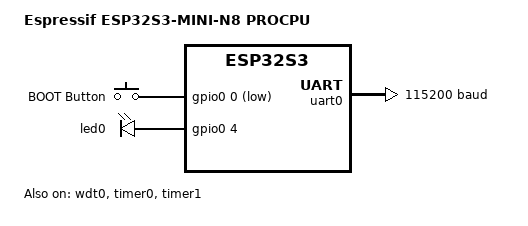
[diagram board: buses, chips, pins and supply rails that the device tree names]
/*
* Copyright (c) 2022-2025 ELIUS FAUSTINE
*
* SPDX-License-Identifier: Apache-2.0
*/
/dts-v1/;

#include <espressif/esp32s3/esp32s3_mini_n8.dtsi>
#include <zephyr/dt-bindings/input/input-event-codes.h>
#include <zephyr/dt-bindings/input/esp32-touch-sensor-input.h>
#include <espressif/partitions_0x0_amp.dtsi>
#include "esp32s3_mini_n8-pinctrl.dtsi"

/ {
	model = "Espressif ESP32S3-MINI-N8 PROCPU";
	compatible = "espressif,esp32s3";
	
	aliases {
		watchdog0 = &wdt0;
		uart-0 = &uart0;
		sw0 = &button0;
		led-0 = &led0;
	};
	chosen {
		zephyr,sram = &sram1;
		zephyr,console = &uart0;
		zephyr,shell-uart = &uart0;
		zephyr,flash = &flash0;
		zephyr,code-partition = &slot0_partition;
		zephyr,bt-hci = &esp32_bt_hci;
	};
	
	buttons {
		compatible = "gpio-keys";
		
		button0: button_0 {
			gpios = <&gpio0 0 (GPIO_PULL_UP | GPIO_ACTIVE_LOW)>;
			label = "BOOT Button";
			zephyr,code = <INPUT_KEY_0>;
		};
	};
	
	led {
		compatible = "gpio-leds";
		led0: d4 {
			gpios = <&gpio0 4 GPIO_ACTIVE_HIGH>;
		};
	};
	
};

&uart0 {
	status = "okay";
	current-speed = <115200>;
	pinctrl-0 = <&uart0_default>;
	pinctrl-names = "default";
};

&gpio0 {
	status = "okay";
};

&wdt0 {
	status = "okay";
};

&timer0 {
	status = "okay";
};

&timer1 {
	status = "okay";
};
